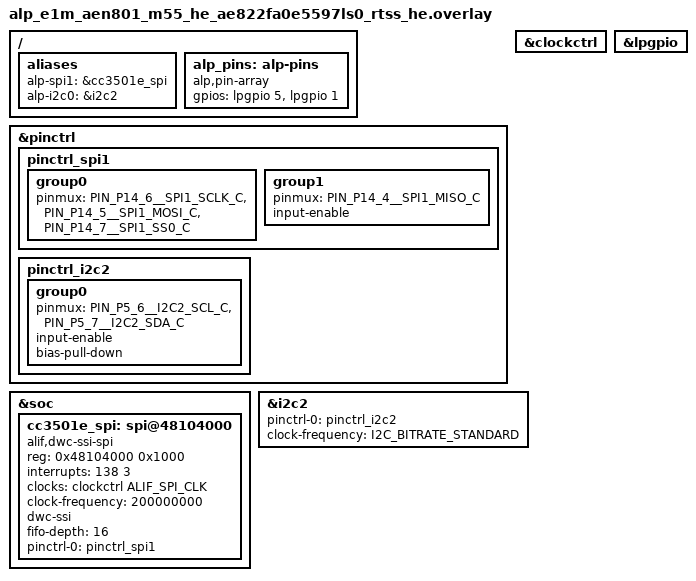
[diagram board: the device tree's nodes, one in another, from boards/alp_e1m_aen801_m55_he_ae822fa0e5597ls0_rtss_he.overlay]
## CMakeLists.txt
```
# SPDX-License-Identifier: Apache-2.0

cmake_minimum_required(VERSION 3.20)

find_package(Zephyr REQUIRED HINTS $ENV{ZEPHYR_BASE})
project(aen_cc3501e_gpio LANGUAGES C)

target_sources(app PRIVATE src/main.c)
# Reusable SoM bring-up helper (cc3501e_bridge_bringup): the one-call CC3501E bridge
# init the example + applications use. Copyable template -- see cc3501e_bridge.h.
target_sources(app PRIVATE src/cc3501e_bridge.c)
# E1M-AEN GPIO-proxy route table: strong override of the WEAK
# cc3501e_gpio_routes[] in src/backends/gpio/cc3501e_proxy_routes_weak.c
# (E1M IO pin_id -> raw CC3501E GPIO). Auto-generated by
# scripts/gen_cc3501e_gpio_routes.py -- do not edit by hand, regenerate.
# Built unconditionally; only consulted when CONFIG_ALP_SDK_GPIO_CC3501E_PROXY
# is enabled (prj.conf).
target_sources(app PRIVATE src/cc3501e_gpio_routes.c)
```

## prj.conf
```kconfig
# SPDX-License-Identifier: Apache-2.0
#
# CONFIG_SPI / CONFIG_GPIO are pulled in from board.yaml's `peripherals:`
# block (via the generated alp.conf); this file carries only the console.
CONFIG_PRINTK=y
CONFIG_LOG=y

# The reset sequence + GPIO-proxy ops use busy/sleep waits; a generous
# main-thread stack keeps the (modest) driver scratch buffers comfortable.
CONFIG_MAIN_STACK_SIZE=4096

# Link the app at the HE MRAM app partition (0x80010000) so its vector table
# matches the ATOC load address (app-zephyr-he.json mramAddress=0x80010000).
# FLASH_BASE is the full MRAM (0x80000000); without this 0x10000 offset the
# image links at 0x80000000 and the SES boots it 64 KB low -> fault/no-boot.
CONFIG_FLASH_LOAD_OFFSET=0x10000

# Route the proxied E1M IOs (cc3501e_gpio_routes[] in src/cc3501e_gpio_routes.c)
# through the CC3501E bridge: alp_gpio_open(ALP_E1M_GPIO_IOxx) for a mapped IO goes over
# the inter-chip link; the Alif's own pins delegate to the platform GPIO driver.
# This demo drives the proxy directly via the cc3501e_gpio_* calls, but building the
# proxy backend keeps the attach call (cc3501e_bridge_bringup) wired the same way an
# application that uses alp_gpio_open(ALP_E1M_GPIO_IO13) would expect.
CONFIG_ALP_SDK_GPIO_CC3501E_PROXY=y
```

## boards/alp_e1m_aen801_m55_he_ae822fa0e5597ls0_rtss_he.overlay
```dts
/*
 * Copyright (c) 2026 Alp Lab AB
 * SPDX-License-Identifier: Apache-2.0
 *
 * Inter-chip wiring for the CC3501E GPIO-proxy demo on the E1M-AEN801 (Alif
 * Ensemble E8, M55-HE).  Identical to the aen-cc3501e-bringup overlay -- the
 * GPIO proxy + camera-enable ops ride the SAME inter-chip SPI1 link + the two
 * host-driven control nets, all from metadata/e1m_modules/aen/inter-chip.tsv:
 *
 *   SPI1.SCK  P14_6   SPI1.MOSI P14_5   SPI1.MISO P14_4   (-> CC3501E GPIO_27/28/29)
 *   WIFI_EN   P15_5 (lpgpio 5)          E_WIFI.NRST P15_1_FLEX (lpgpio 1)
 *
 * "P15" is the Alif low-power GPIO island (lpgpio @ 0x42002000); the
 * _FLEX pads are its pins.  P14 is a main-domain port used here purely as
 * the SPI1 function via pinctrl, so no gpio14 controller node is needed.
 *
 * SPI1 DATA PATH BENCH-VALIDATED 2026-06-20 (E1M-AEN801, M55-HE): the GPIO
 * proxy round-trips over this link (docs/cc3501e-gpio-bench.md, pass=8 fail=0),
 * confirming the P14_4/5/6 pinctrl (SPI1 alt-2, `_C` suffix), the
 * `spi@48104000` base, the LP-GPIO mux (alt-0 default), and the
 * `clock-frequency` workaround.  Still UNCONFIRMED: the SPI1 IRQ number
 * (`interrupts = <138 3>` below). The bridge is hardware-framed by SS0, but
 * this example does not exercise an interrupt-driven SPI path; confirm the IRQ
 * against the AE822 TRM before relying on it.  Addresses/IRQs are still
 * transcribed from the Apache-2.0 alifsemi/zephyr_alif fork + the AE822 TRM
 * (as in zephyr/dts/alif/ensemble_e8_peripherals.dtsi).
 *
 * Also enables i2c2 (P5_6 SCL_C / P5_7 SDA_C) + the `alp-i2c0` alias -- the
 * on-module EEPROM manifest bus alp_hw_info_read() opens as bus_id 0.
 * Without it the manifest read structurally cannot succeed and the banner
 * falls back to the raw board target instead of the SoM identity; see #1870.
 * Same pinctrl (input-enable + bias-pull-down) as
 * examples/peripheral-io/alp-console's bench-validated overlay -- do NOT
 * "correct" the pull direction.
 */

#include <zephyr/dt-bindings/pinctrl/alif-ensemble-pinctrl.h>
#include <zephyr/dt-bindings/gpio/gpio.h>
#include <zephyr/dt-bindings/i2c/i2c.h>

&pinctrl {
	/*
	 * SPI1 master on P14_6 (SCK) / P14_5 (MOSI) / P14_4 (MISO).
	 *
	 * RESOLVED against alif-ensemble-pinctrl.h: the SPI1 functions on these
	 * three pads are alt-2, named with the `_C` suffix
	 * (PIN_P14_6__SPI1_SCLK_C = ALIF_PINMUX(14, 6, 2), etc.).  input-enable
	 * on MISO so the pad can sense the slave's drive (the same read-enable
	 * requirement the I2C pads need on this SoC).
	 */
	pinctrl_spi1: pinctrl_spi1 {
		group0 {
			/* Hardware SS0 chip-select (P14_7 = SPI1_SS0_C) -- dwc-ssi master
			 * drives SS0 per transfer to frame the CC3501E slave.  The slave's
			 * SPIWFF3DMA only shifts bytes while its CS is asserted, so WITHOUT
			 * this pad muxed the bridge is dead (PING never round-trips) -- this
			 * example's overlay had drifted to the pre-r2 CS-less 3-wire wiring
			 * (missing SS0) while its own comment claimed SS0 was muxed; #708. */
			pinmux = <PIN_P14_6__SPI1_SCLK_C>, <PIN_P14_5__SPI1_MOSI_C>,
				 <PIN_P14_7__SPI1_SS0_C>;
		};
		group1 {
			pinmux = <PIN_P14_4__SPI1_MISO_C>;
			input-enable;
		};
	};

	/* I2C2 master (EEPROM manifest bus): SCL P5_6 / SDA P5_7 (_C).  Same
	 * pad config as alp-console's bench-validated overlay -- input-enable
	 * for ACK-detect, bias-pull-down (the pad DSC value Alif's reference
	 * uses; the bus is pulled up on the carrier via R95/R96). */
	pinctrl_i2c2: pinctrl_i2c2 {
		group0 {
			pinmux = <PIN_P5_6__I2C2_SCL_C>, <PIN_P5_7__I2C2_SDA_C>;
			input-enable;
			bias-pull-down;
		};
	};
};

/*
 * DWC_ssi SPI1 (AHB) -- the on-SoM CC3501E inter-chip link.  Deliberately
 * NOT in ensemble_e8_peripherals.dtsi (that dtsi declares only the
 * customer-facing edge SPI0); this is the SoM-internal Wi-Fi link, so it
 * lives in the consuming app's overlay.  Same driver + flags as spi0
 * (compatible "alif,dwc-ssi-spi", dwc-ssi layout, fifo-depth 16,
 * frequency-only ALIF_SPI_CLK).
 *
 * reg 0x48104000 = SPI1 base (spi0 is 0x48103000, +0x1000/instance).
 * BENCH-TBD: interrupts = <138 3> follows the consecutive pattern from
 * spi0's IRQ 137 -- confirm SPI1_IRQ against the fork's e1.dtsi / TRM.
 *
 * No cs-gpios: P14_7 is muxed as SPI1_SS0_C above and the dwc-ssi peripheral
 * drives hardware SS0 per transfer.  The host opens ALP_SPI_NO_CS so no GPIO CS
 * is installed, allowing the SPI driver to use its hardware slave-select path.
 */
&clockctrl {
	status = "okay";
};

&soc {
	cc3501e_spi: spi@48104000 {
		compatible = "alif,dwc-ssi-spi";
		#address-cells = <1>;
		#size-cells = <0>;
		reg = <0x48104000 0x1000>;
		interrupts = <138 3>;          /* BENCH-TBD: confirm SPI1 IRQ */
		clocks = <&clockctrl ALIF_SPI_CLK>;
		/*
		 * ROOT-CAUSE FIX 2026-06-16: spi_dw_alif's configure takes the
		 * clock-control path when no clock-frequency is set, and that path
		 * fails (-EINVAL) for the gateless dummy ALIF_SPI_CLK -> every
		 * transceive returned ALP_ERR_INVAL with zero SCLK (witness fail_step=1,
		 * zerr=-EINVAL). Providing the SSI input clock here makes the driver
		 * use it directly and skip the failing clock-control path. The SSI
		 * functional clock is 200 MHz (E8 HWRM); BAUDR = clk/freq_hz.
		 */
		clock-frequency = <200000000>; /* real SSI functional clock (was mis-set 400M -- halves the requested SCLK; proven via BAUDR scaling, parity with the bringup/tour overlays) */
		dwc-ssi;
		fifo-depth = <16>;
		pinctrl-0 = <&pinctrl_spi1>;
		pinctrl-names = "default";
		status = "okay";
	};
};

/*
 * Enable the LP GPIO island so WIFI_EN (P15_5) and E_WIFI.NRST
 * (P15_1_FLEX) are drivable as outputs.  gpio_dw needs no clocks/pinctrl
 * on the controller, and the pad->GPIO mux needs no pinctrl group either:
 * RESOLVED against alif-ensemble-pinctrl.h -- P15_1/P15_5 function 0 (the
 * reset default) IS LPGPIO (PIN_P15_x__LPGPIO = ALIF_PINMUX(15, x, 0)).
 */
&lpgpio {
	status = "okay";
};

&i2c2 {
	status = "okay";
	pinctrl-0 = <&pinctrl_i2c2>;
	pinctrl-names = "default";
	clock-frequency = <I2C_BITRATE_STANDARD>;   /* 100 kHz */
};

/ {
	aliases {
		/* bus_id 1 in alp_spi_open() -> this controller. */
		alp-spi1 = &cc3501e_spi;
		alp-i2c0 = &i2c2;   /* bus 0 for alp_hw_info_read() -> EEPROM manifest */
	};

	/*
	 * Compact 2-entry control array for the SoM-internal CC3501E nets, in
	 * the order the app's CC3501E_BRIDGE_PIN_* indices expect.  These are NOT
	 * E1M edge pads, so this app intentionally does NOT use the 52-slot
	 * positional E1M map; a production board file appends such SoM-internal
	 * control nets after the E1M pad slots.
	 */
	alp_pins: alp-pins {
		compatible = "alp,pin-array";
		gpios = <&lpgpio 5 GPIO_ACTIVE_HIGH>,   /* [0] WIFI_EN     (P15_5)      */
			<&lpgpio 1 GPIO_ACTIVE_HIGH>;   /* [1] E_WIFI.NRST (P15_1_FLEX) */
	};
};
```

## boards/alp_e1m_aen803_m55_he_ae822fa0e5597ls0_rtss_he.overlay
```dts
/*
 * Copyright (c) 2026 Alp Lab AB
 * SPDX-License-Identifier: Apache-2.0
 *
 * Inter-chip wiring for the CC3501E GPIO-proxy demo on the E1M-AEN803 (Alif
 * Ensemble E8, M55-HE).  Identical to the aen-cc3501e-bringup overlay -- the
 * GPIO proxy + camera-enable ops ride the SAME inter-chip SPI1 link + the two
 * host-driven control nets, all from metadata/e1m_modules/aen/inter-chip.tsv:
 *
 *   SPI1.SCK  P14_6   SPI1.MOSI P14_5   SPI1.MISO P14_4   (-> CC3501E GPIO_27/28/29)
 *   WIFI_EN   P15_5 (lpgpio 5)          E_WIFI.NRST P15_1_FLEX (lpgpio 1)
 *
 * "P15" is the Alif low-power GPIO island (lpgpio @ 0x42002000); the
 * _FLEX pads are its pins.  P14 is a main-domain port used here purely as
 * the SPI1 function via pinctrl, so no gpio14 controller node is needed.
 *
 * SPI1 DATA PATH BENCH-VALIDATED 2026-06-20 (E1M-AEN801, M55-HE): the GPIO
 * proxy round-trips over this link (docs/cc3501e-gpio-bench.md, pass=8 fail=0),
 * confirming the P14_4/5/6 pinctrl (SPI1 alt-2, `_C` suffix), the
 * `spi@48104000` base, the LP-GPIO mux (alt-0 default), and the
 * `clock-frequency` workaround.  Still UNCONFIRMED: the SPI1 IRQ number
 * (`interrupts = <138 3>` below). The bridge is hardware-framed by SS0, but
 * this example does not exercise an interrupt-driven SPI path; confirm the IRQ
 * against the AE822 TRM before relying on it.  Addresses/IRQs are still
 * transcribed from the Apache-2.0 alifsemi/zephyr_alif fork + the AE822 TRM
 * (as in zephyr/dts/alif/ensemble_e8_peripherals.dtsi).  This SPI1/GPIO pad
 * path is identical on the AEN803's same AE822 M55-HE die, but this
 * backfilled overlay has not itself been separately bench-run on AEN803
 * (Refs #2128) -- unbuilt as of this PR.
 *
 * Also enables i2c2 (P5_6 SCL_C / P5_7 SDA_C) + the `alp-i2c0` alias -- the
 * on-module EEPROM manifest bus alp_hw_info_read() opens as bus_id 0.
 * Without it the manifest read structurally cannot succeed and the banner
 * falls back to the raw board target instead of the SoM identity; see #1870.
 * Same pinctrl (input-enable + bias-pull-down) as
 * examples/peripheral-io/alp-console's bench-validated overlay -- do NOT
 * "correct" the pull direction.
 */

#include <zephyr/dt-bindings/pinctrl/alif-ensemble-pinctrl.h>
#include <zephyr/dt-bindings/gpio/gpio.h>
#include <zephyr/dt-bindings/i2c/i2c.h>

&pinctrl {
	/*
	 * SPI1 master on P14_6 (SCK) / P14_5 (MOSI) / P14_4 (MISO).
	 *
	 * RESOLVED against alif-ensemble-pinctrl.h: the SPI1 functions on these
	 * three pads are alt-2, named with the `_C` suffix
	 * (PIN_P14_6__SPI1_SCLK_C = ALIF_PINMUX(14, 6, 2), etc.).  input-enable
	 * on MISO so the pad can sense the slave's drive (the same read-enable
	 * requirement the I2C pads need on this SoC).
	 */
	pinctrl_spi1: pinctrl_spi1 {
		group0 {
			/* Hardware SS0 chip-select (P14_7 = SPI1_SS0_C) -- dwc-ssi master
			 * drives SS0 per transfer to frame the CC3501E slave.  The slave's
			 * SPIWFF3DMA only shifts bytes while its CS is asserted, so WITHOUT
			 * this pad muxed the bridge is dead (PING never round-trips) -- this
			 * example's overlay had drifted to the pre-r2 CS-less 3-wire wiring
			 * (missing SS0) while its own comment claimed SS0 was muxed; #708. */
			pinmux = <PIN_P14_6__SPI1_SCLK_C>, <PIN_P14_5__SPI1_MOSI_C>,
				 <PIN_P14_7__SPI1_SS0_C>;
		};
		group1 {
			pinmux = <PIN_P14_4__SPI1_MISO_C>;
			input-enable;
		};
	};

	/* I2C2 master (EEPROM manifest bus): SCL P5_6 / SDA P5_7 (_C).  Same
	 * pad config as alp-console's bench-validated overlay -- input-enable
	 * for ACK-detect, bias-pull-down (the pad DSC value Alif's reference
	 * uses; the bus is pulled up on the carrier via R95/R96). */
	pinctrl_i2c2: pinctrl_i2c2 {
		group0 {
			pinmux = <PIN_P5_6__I2C2_SCL_C>, <PIN_P5_7__I2C2_SDA_C>;
			input-enable;
			bias-pull-down;
		};
	};
};

/*
 * DWC_ssi SPI1 (AHB) -- the on-SoM CC3501E inter-chip link.  Deliberately
 * NOT in ensemble_e8_peripherals.dtsi (that dtsi declares only the
 * customer-facing edge SPI0); this is the SoM-internal Wi-Fi link, so it
 * lives in the consuming app's overlay.  Same driver + flags as spi0
 * (compatible "alif,dwc-ssi-spi", dwc-ssi layout, fifo-depth 16,
 * frequency-only ALIF_SPI_CLK).
 *
 * reg 0x48104000 = SPI1 base (spi0 is 0x48103000, +0x1000/instance).
 * BENCH-TBD: interrupts = <138 3> follows the consecutive pattern from
 * spi0's IRQ 137 -- confirm SPI1_IRQ against the fork's e1.dtsi / TRM.
 *
 * No cs-gpios: P14_7 is muxed as SPI1_SS0_C above and the dwc-ssi peripheral
 * drives hardware SS0 per transfer.  The host opens ALP_SPI_NO_CS so no GPIO CS
 * is installed, allowing the SPI driver to use its hardware slave-select path.
 */
&clockctrl {
	status = "okay";
};

&soc {
	cc3501e_spi: spi@48104000 {
		compatible = "alif,dwc-ssi-spi";
		#address-cells = <1>;
		#size-cells = <0>;
		reg = <0x48104000 0x1000>;
		interrupts = <138 3>;          /* BENCH-TBD: confirm SPI1 IRQ */
		clocks = <&clockctrl ALIF_SPI_CLK>;
		/*
		 * ROOT-CAUSE FIX 2026-06-16: spi_dw_alif's configure takes the
		 * clock-control path when no clock-frequency is set, and that path
		 * fails (-EINVAL) for the gateless dummy ALIF_SPI_CLK -> every
		 * transceive returned ALP_ERR_INVAL with zero SCLK (witness fail_step=1,
		 * zerr=-EINVAL). Providing the SSI input clock here makes the driver
		 * use it directly and skip the failing clock-control path. The SSI
		 * functional clock is 200 MHz (E8 HWRM); BAUDR = clk/freq_hz.
		 */
		clock-frequency = <200000000>; /* real SSI functional clock (was mis-set 400M -- halves the requested SCLK; proven via BAUDR scaling, parity with the bringup/tour overlays) */
		dwc-ssi;
		fifo-depth = <16>;
		pinctrl-0 = <&pinctrl_spi1>;
		pinctrl-names = "default";
		status = "okay";
	};
};

/*
 * Enable the LP GPIO island so WIFI_EN (P15_5) and E_WIFI.NRST
 * (P15_1_FLEX) are drivable as outputs.  gpio_dw needs no clocks/pinctrl
 * on the controller, and the pad->GPIO mux needs no pinctrl group either:
 * RESOLVED against alif-ensemble-pinctrl.h -- P15_1/P15_5 function 0 (the
 * reset default) IS LPGPIO (PIN_P15_x__LPGPIO = ALIF_PINMUX(15, x, 0)).
 */
&lpgpio {
	status = "okay";
};

&i2c2 {
	status = "okay";
	pinctrl-0 = <&pinctrl_i2c2>;
	pinctrl-names = "default";
	clock-frequency = <I2C_BITRATE_STANDARD>;   /* 100 kHz */
};

/ {
	aliases {
		/* bus_id 1 in alp_spi_open() -> this controller. */
		alp-spi1 = &cc3501e_spi;
		alp-i2c0 = &i2c2;   /* bus 0 for alp_hw_info_read() -> EEPROM manifest */
	};

	/*
	 * Compact 2-entry control array for the SoM-internal CC3501E nets, in
	 * the order the app's CC3501E_BRIDGE_PIN_* indices expect.  These are NOT
	 * E1M edge pads, so this app intentionally does NOT use the 52-slot
	 * positional E1M map; a production board file appends such SoM-internal
	 * control nets after the E1M pad slots.
	 */
	alp_pins: alp-pins {
		compatible = "alp,pin-array";
		gpios = <&lpgpio 5 GPIO_ACTIVE_HIGH>,   /* [0] WIFI_EN     (P15_5)      */
			<&lpgpio 1 GPIO_ACTIVE_HIGH>;   /* [1] E_WIFI.NRST (P15_1_FLEX) */
	};
};
```

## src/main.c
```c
/*
 * Copyright 2026 Alp Lab AB
 * SPDX-License-Identifier: Apache-2.0
 *
 * aen-cc3501e-gpio -- drive + read a PROXIED GPIO and the camera-enable
 * LDOs on the on-module TI CC3501E Wi-Fi 6 + BLE 5.4 coprocessor, from the
 * Alif Ensemble E8 host (M55-HE), over the inter-chip SPI bridge.
 *
 * This is the *Alif (host) side*; its peer is the ALP-authored firmware
 * that runs on the CC3501E's own Cortex-M33 (cc3501e-bridge-firmware:, embedded
 * per ADR 0015 -- like the gd32-bridge).  It is the sibling of
 * examples/aen/aen-cc3501e-bringup: it brings the bridge up the SAME way
 * (one call to cc3501e_bridge_bringup()), then exercises a different slice
 * of the firmware -- the GPIO proxy + camera enables -- instead of the
 * Wi-Fi/BLE control path.
 *
 *
 * ==== WHAT IS THE "GPIO PROXY"? ====================================
 *
 * Several E1M edge IO pads on the AEN SoM are NOT wired to an Alif pin --
 * they are wired to a *CC3501E* GPIO.  The CC3501E sits between the Alif
 * and those pads.  So when the application asks for "IO13", the SDK cannot
 * toggle an Alif register; it must ask the CC3501E firmware to toggle the
 * pad on its behalf, over the SPI bridge.  That indirection -- host op ->
 * bridge frame -> CC3501E drives the pad -- is the GPIO *proxy*.
 *
 * Two ways to use it:
 *
 *   1. PORTABLE (what an application normally writes):
 *        alp_gpio_t *io = alp_gpio_open(ALP_E1M_GPIO_IO13);
 *        alp_gpio_configure(io, ALP_GPIO_OUTPUT, ALP_GPIO_PULL_NONE);
 *        alp_gpio_write(io, true);
 *      With CONFIG_ALP_SDK_GPIO_CC3501E_PROXY=y and the route table in
 *      src/cc3501e_gpio_routes.c, the SDK silently routes ALP_E1M_GPIO_IO13
 *      over the bridge to raw CC3501E GPIO_13 -- the app never names the
 *      coprocessor.  (This build enables that backend so the bring-up
 *      helper's alp_gpio_cc3501e_attach() runs, exactly as a portable app
 *      would expect.)
 *
 *   2. DIRECT (what THIS demo does, to make the bridge op visible):
 *        cc3501e_gpio_configure(&fw, 13 [raw pad], DIR_OUTPUT, PULL_NONE, t);
 *        cc3501e_gpio_write(&fw, 13, true, t);
 *      Here `pad` is the RAW CC3501E GPIO index.  We call the chip driver
 *      directly so each bridge transaction is explicit in the teaching
 *      log -- it is the same wire op the portable path emits underneath.
 *
 * The route table (src/cc3501e_gpio_routes.c) ties ALP_E1M_GPIO_IO13 -> raw
 * CC3501E GPIO 13, so "pad 13" below is the same pad a portable
 * alp_gpio_open(ALP_E1M_GPIO_IO13) would reach.
 *
 *
 * ==== THE r2 HOST-IRQ CAVEAT (READ BEFORE USING INTERRUPTS) ========
 *
 * This HW rev uses hardware SS0 for SPI framing and an OPTIONAL READY input
 * for per-phase gating (unwired, fw->ready_pin stays NULL, in this app --
 * see src/cc3501e_bridge.c), but it still does not expose GPIO edge events
 * as portable application callbacks.  The Alif is always the SPI master;
 * the CC3501E is always the slave.  Without a dedicated async event
 * delivery path, the slave cannot
 * spontaneously tell the master "an edge happened on a GPIO".  So:
 *
 *   - cc3501e_gpio_set_interrupt() ARMS the edge on the CC3501E's own GPIO
 *     controller -- that part is real, it latches edges in the coprocessor.
 *   - but the async ALP_CC3501E_EVT_GPIO_INTERRUPT frame is not a portable
 *     callback path in this example.  The host must poll cc3501e_gpio_read() to
 *     observe a level change; the armed interrupt does not call you back.
 *
 * The step below therefore only proves the ARM round-trips; do not build a
 * design that depends on EVT_GPIO_INTERRUPT delivery on this rev.
 *
 *
 * ==== BENCH CONTRACT ===============================================
 *
 * Each step prints ONE stable line a sibling bench script greps:
 *     GPIO_TEST: <step> <PASS|FAIL>
 * with these exact <step> tokens, in order:
 *     gpio_config_out gpio_write_high gpio_write_low gpio_config_in
 *     gpio_read cam_enable cam_disable gpio_irq_arm
 * and a final:
 *     GPIO_TEST: SUMMARY pass=<n> fail=<n>
 * Keep these strings byte-for-byte -- the grep depends on them.
 *
 * NOTE ON native_sim: the CI build target (native_sim/native/64) has only
 * an EMULATED SPI controller with no CC3501E attached, so every bridge op
 * times out and the contract lines print FAIL there.  That is EXPECTED:
 * native_sim proves the example *builds* (twister build_only); the
 * PASS/FAIL contract is a SILICON bench signal, read on real hardware.
 *
 * This file is ~50 % comment by design: examples are documentation for
 * hand-written firmware, not just runnable code.
 */

#include <stdio.h>

#include <zephyr/kernel.h>

#include "alp/peripheral.h"
#include "alp/chips/cc3501e.h"

#include "cc3501e_bridge.h" /* cc3501e_bridge_bringup() -- the SoM bring-up helper */

/*
 * The proxied pad this demo drives.  RAW CC3501E GPIO index 13, which the
 * route table (src/cc3501e_gpio_routes.c) maps to the portable E1M IO
 * ALP_E1M_GPIO_IO13 (= I2S_SELECT on the E1M-AEN netlist).  Driving it has no
 * destructive side-effect on the bench, which is why it is the demo pad.
 */
#define DEMO_PAD 13u

/*
 * Camera-enable LDO index.  0 = CAM_EN_LDO0 (CC35 GPIO_1); 1 = CAM_EN_LDO1
 * (CC35 GPIO_0) per the BDE-BW35N U4 netlist.  We exercise LDO0.
 */
#define DEMO_CAM 0u

/*
 * Per-request budget for the synchronous GPIO/camera bridge ops.  These
 * are fast in the firmware (no worker, unlike the Wi-Fi helpers), so a
 * short timeout is plenty; it also bounds how long native_sim sits on each
 * (failing) op before recording FAIL and moving on.
 */
#define DEMO_OP_TIMEOUT_MS 100u

/*
 * ==== WHY THIS EXAMPLE NEEDS A LIVENESS GATE (read before touching #708) ==
 *
 * cc3501e_bridge_bringup() -> cc3501e_reset() only does a BLIND boot-settle
 * delay (see chips/cc3501e/cc3501e_core.c) -- it never exchanges a byte with
 * the module, so it returns as soon as its own timer expires, NOT when the
 * firmware is actually answering.  The --wifi --ble image is slow to arm its
 * SPI slave: lwIP's tcpip_init() and the crypto/Board_init sequence run
 * BEFORE transport_spi_init(), and the Puya cold-boot flash bug (see
 * cc3501e_hard_reset()'s comment) sometimes needs a SECOND hard reset before
 * the module answers at all.  Meanwhile each of the 8 gpio/cam ops below has
 * only a DEMO_OP_TIMEOUT_MS (100 ms) budget -- ~0.9 s total for all 8 -- so
 * without a gate they race the boot and ALL eight TIMEOUT before the slave
 * is armed, even though the link comes up fine a second or two later.  (The
 * bringup soak already has this "hard-reset again if one re-boot is not
 * enough" retry -- cc3501e_core.c:119-121 -- this gate is the same idea
 * applied here, mirroring aen-cc3501e-companion-tour's tour_ping().)
 *
 * The fix is NOT a bigger DEMO_OP_TIMEOUT_MS (that just slows down every
 * op, including the ones that are genuinely broken) -- it is to not START
 * the ops until a cheap, zero-payload PING actually round-trips.
 */
#define GPIO_PING_RETRIES 25u  /* poll-by-repeat budget per attempt, mirrors tour_ping() */
#define GPIO_PING_GAP_MS  200u /* gap between PING attempts (5 s worst case per attempt) */
#define GPIO_LINK_REBOOTS 3u   /* extra cc3501e_hard_reset() attempts if PING never lands */

/*
 * Emit one bench-contract line and fold the result into the running
 * tally.  `ok` is the boolean a step computed from its alp_status_t; we
 * print the exact "GPIO_TEST: <step> PASS|FAIL" the bench script greps and
 * bump pass/fail so main() can print the SUMMARY at the end.
 */
static void report(const char *step, bool ok, unsigned *pass, unsigned *fail)
{
	printf("GPIO_TEST: %s %s\n", step, ok ? "PASS" : "FAIL");
	if (ok) {
		(*pass)++;
	} else {
		(*fail)++;
	}
}

/*
 * Liveness gate -- see the "WHY" block above DEMO_OP_TIMEOUT_MS.  Spins a
 * zero-payload PING up to GPIO_PING_RETRIES times (GPIO_PING_GAP_MS apart);
 * PING is cheap (no worker, no radio) so this is a fast poll, not a slow
 * one.  If a whole PING attempt never lands, cc3501e_hard_reset() gives the
 * module a second boot (the Puya cold-boot workaround -- the first boot can
 * simply fail to launch the vendor image) and the PING loop runs again, up
 * to GPIO_LINK_REBOOTS times.  Returns true once a PING succeeds.
 */
static bool gpio_wait_for_link(cc3501e_t *fw)
{
	for (unsigned reboot = 0u; reboot <= GPIO_LINK_REBOOTS; ++reboot) {
		for (unsigned i = 0u; i < GPIO_PING_RETRIES; ++i) {
			if (cc3501e_ping(fw) == ALP_OK) {
				printf("[cc3501e-gpio] link up (PING ok after %u) -- running gpio ops\n", i + 1u);
				return true;
			}
			alp_delay_ms(GPIO_PING_GAP_MS);
		}
		/* A full PING budget elapsed with no reply -- the module may have
		 * hit the Puya cold-boot bug (first boot never launches the vendor
		 * image).  Give it one more re-boot with the rails kept up and try
		 * again, unless we are already on the last allowed attempt. */
		if (reboot < GPIO_LINK_REBOOTS) {
			printf("[cc3501e-gpio] PING never answered after %u attempts -- issuing "
			       "hard reset %u/%u and retrying\n",
			       GPIO_PING_RETRIES,
			       reboot + 1u,
			       GPIO_LINK_REBOOTS);
			(void)cc3501e_hard_reset(fw);
		}
	}
	printf("[cc3501e-gpio] CC3501E never answered PING after %u hard reset(s) -- the gpio "
	       "ops below will still run (and report FAIL) so the bench SUMMARY stays complete; "
	       "check WIFI_EN power, the SPI1 pinmux, and that the --wifi --ble firmware is "
	       "actually flashed\n",
	       GPIO_LINK_REBOOTS);
	return false;
}

int main(void)
{
	printf("\n[cc3501e-gpio] E1M-AEN CC3501E GPIO-proxy + camera-enable demo\n");

	unsigned pass = 0u;
	unsigned fail = 0u;

	/*
	 * Bring up the SoM's CC3501E coprocessor in ONE call -- exactly like
	 * aen-cc3501e-bringup.  cc3501e_bridge_bringup() opens the inter-chip
	 * SPI bridge + the WIFI_EN/nRESET control pins, binds them, attaches
	 * the GPIO proxy backend (so a portable alp_gpio_open(ALP_E1M_GPIO_IO13)
	 * would route over the bridge), and runs the power + reset sequence
	 * (TI SWRU626 + the Puya cold-boot hard-reset).  Leaves WIFI_EN HIGH.
	 *
	 * STATIC, not a stack local (#1868): sizeof(cc3501e_t) is ~32 KB
	 * (measured -- rx_scratch/tx_scratch/wifi_scan_buf/ble_scan_buf/
	 * evt_buf/sock_buf/spi1_{tx,rx}_buf are each sized off the v5
	 * ALP_CC3501E_MAX_PAYLOAD=4096) against CONFIG_MAIN_STACK_SIZE=4096,
	 * so as a local the prologue's frame reservation alone crosses
	 * PSPLIM and the M55 raises a UsageFault at main() entry -- before
	 * even this function's first printf runs.  Same fix, same reason,
	 * as aen-cc3501e-bringup's `fw`.
	 */
	static cc3501e_t fw;
	alp_status_t     s = cc3501e_bridge_bringup(&fw);
	if (s == ALP_ERR_NOT_PRESENT_ON_THIS_SOC) {
		/* The backend authority itself says the SPI bus / control pins are
		 * absent (wrong board overlay) -- a bench/board limitation, not a
		 * bug in this app (same rule as an ALP_ERR_NOSUPPORT boot-authority
		 * answer elsewhere in this diff: aen-alp-rpc/src/main.c,
		 * aen-dualcore-doorbell/src/main.c). Nothing to drive -- bail. */
		printf("[cc3501e-gpio] bridge bring-up skipped (SPI bus %u / WIFI_EN+nRESET "
		       "absent? err=%d) -- check the board overlay\n",
		       CC3501E_BRIDGE_SPI_BUS_ID,
		       (int)alp_last_error());
		printf("RESULT SKIP: cc3501e_bridge_bringup -> NOT_PRESENT_ON_THIS_SOC (SPI bus %u / "
		       "WIFI_EN+nRESET absent? err=%d)\n",
		       CC3501E_BRIDGE_SPI_BUS_ID,
		       (int)alp_last_error());
		return 0;
	}
	printf("[cc3501e-gpio] cc3501e bridge bring-up -> %d%s\n",
	       (int)s,
	       (s == ALP_ERR_NOSUPPORT) ? " (control pins not bound?)" : "");

	/*
	 * Liveness gate -- see #708.  cc3501e_bridge_bringup() only waits out a
	 * BLIND boot-settle timer (no wire exchange), so it can return before
	 * the --wifi --ble firmware has actually armed its SPI slave.  Do not
	 * skip straight to the 8 gpio/cam ops (each has only a 100 ms budget):
	 * confirm the link is live with a cheap PING first, retrying through
	 * extra hard resets if needed.  We deliberately do NOT early-return on
	 * total failure -- the bench script's grep contract requires all 8 step
	 * lines plus the SUMMARY, so the ops still run below (and will FAIL,
	 * correctly reporting a dead link instead of going silent).
	 */
	(void)gpio_wait_for_link(&fw);

	/*
	 * Step 1 -- configure the proxied pad as a push-pull OUTPUT with no
	 * internal pull.  This is GPIO_CONFIGURE (0x50) over the bridge: the
	 * host hands the CC3501E the pad index + direction + pull and the
		 * firmware programs its own GPIO controller.  ALP_OK = the firmware
		 * accepted the config and answered over the hardware-framed bridge.
	 */
	s = cc3501e_gpio_configure(
	    &fw, DEMO_PAD, ALP_CC3501E_GPIO_DIR_OUTPUT, ALP_CC3501E_GPIO_PULL_NONE, DEMO_OP_TIMEOUT_MS);
	report("gpio_config_out", s == ALP_OK, &pass, &fail);

	/*
	 * Step 2 -- drive the pad HIGH.  GPIO_WRITE (0x51) with level=true.
	 * On silicon a meter on the E1M IO13 pad reads ~3V3 after this.
	 */
	s = cc3501e_gpio_write(&fw, DEMO_PAD, true, DEMO_OP_TIMEOUT_MS);
	report("gpio_write_high", s == ALP_OK, &pass, &fail);

	/*
	 * Step 3 -- drive the pad LOW.  Same op, level=false; the pad returns
	 * to ~0 V.  Writing both levels proves the firmware honours the value
	 * field, not just that the op round-trips.
	 */
	s = cc3501e_gpio_write(&fw, DEMO_PAD, false, DEMO_OP_TIMEOUT_MS);
	report("gpio_write_low", s == ALP_OK, &pass, &fail);

	/*
	 * Step 4 -- reconfigure the SAME pad as an INPUT with the internal
	 * pull-UP enabled.  GPIO_CONFIGURE again, direction=INPUT, pull=UP.
	 * The on-die pull is documented as weak; a board needing a firm level
	 * adds an external resistor.  With nothing else driving the net the
	 * pull-up should make the next read sense HIGH.
	 */
	s = cc3501e_gpio_configure(
	    &fw, DEMO_PAD, ALP_CC3501E_GPIO_DIR_INPUT, ALP_CC3501E_GPIO_PULL_UP, DEMO_OP_TIMEOUT_MS);
	report("gpio_config_in", s == ALP_OK, &pass, &fail);

	/*
	 * Step 5 -- READ the pad back.  GPIO_READ (0x52): the firmware samples
	 * its pad and returns the level in the reply payload.  We print the
	 * sensed level for the bench log; PASS just means the read op itself
	 * succeeded (the actual level depends on what is wired to the pad).
	 */
	bool level = false;
	s          = cc3501e_gpio_read(&fw, DEMO_PAD, &level, DEMO_OP_TIMEOUT_MS);
	if (s == ALP_OK) {
		printf("[cc3501e-gpio] pad %u reads %s\n", DEMO_PAD, level ? "HIGH" : "LOW");
	}
	report("gpio_read", s == ALP_OK, &pass, &fail);

	/*
	 * Step 6 -- ENABLE camera LDO0.  cc3501e_cam_enable(which=0, on=true)
	 * sends CAM_ENABLE (0x60); the firmware asserts the LDO's enable pin
	 * (CC35 GPIO_1).  On a camera-fitted board this powers the sensor rail.
	 */
	s = cc3501e_cam_enable(&fw, DEMO_CAM, true, DEMO_OP_TIMEOUT_MS);
	report("cam_enable", s == ALP_OK, &pass, &fail);

	/*
	 * Step 7 -- DISABLE camera LDO0.  cc3501e_cam_enable(which=0, on=false)
	 * sends CAM_DISABLE (0x61); the firmware deasserts the enable.  We
	 * power it back down so the demo leaves the rail in its idle state.
	 */
	s = cc3501e_cam_enable(&fw, DEMO_CAM, false, DEMO_OP_TIMEOUT_MS);
	report("cam_disable", s == ALP_OK, &pass, &fail);

	/*
	 * Step 8 -- ARM a RISING-edge interrupt on the proxied pad.
	 * GPIO_SET_INTERRUPT (0x53), edge=RISING, enabled=true.
	 *
	 * IMPORTANT (see the caveat at the top): this ONLY arms the edge on
	 * the CC3501E's GPIO controller.  The async EVT_GPIO_INTERRUPT frame is
	 * not a portable callback path in this example.  A PASS here means "the
	 * firmware accepted the arm request", NOT "you will get an interrupt
	 * callback".  To observe the edge today you must POLL cc3501e_gpio_read()
	 * in a loop.  (EDGE_BOTH is unsupported on the CC35xx controller -- arm
	 * RISING or FALLING, never both.)
	 */
	s = cc3501e_gpio_set_interrupt(
	    &fw, DEMO_PAD, ALP_CC3501E_GPIO_EDGE_RISING, true, DEMO_OP_TIMEOUT_MS);
	report("gpio_irq_arm", s == ALP_OK, &pass, &fail);

	/*
	 * Final contract line: the running tally.  A bench run on silicon with
	 * the CC3501E firmware up expects pass=8 fail=0; under native_sim
	 * (emul SPI, no slave) expect pass=0 fail=8 -- the build, not the
	 * round-trip, is what the CI target proves.
	 */
	printf("GPIO_TEST: SUMMARY pass=%d fail=%d\n", (int)pass, (int)fail);

	/* RESULT verdict, gated on the SUMMARY tally above -- report() is the
	 * ONLY thing that increments pass/fail, and every one of the 8 steps
	 * calls it, so fail==0 here means all 8 bridge ops genuinely returned
	 * ALP_OK (not that main() merely reached this line: a dead link fails
	 * every step via gpio_wait_for_link()'s own comment above, and native_sim
	 * -- no CC3501E attached -- always lands here with fail=8). */
	if (fail == 0u) {
		printf("RESULT PASS: all %u cc3501e gpio/cam bridge ops ok\n", pass);
	} else {
		printf("RESULT FAIL: %u/%u cc3501e gpio/cam bridge op(s) failed -- see GPIO_TEST "
		       "lines above\n",
		       fail,
		       pass + fail);
	}

	/* The bridge SPI + control pins are owned by cc3501e_bridge_bringup();
	 * a real app that tears down would add a cc3501e_bridge_teardown(). */
	return 0;
}
```

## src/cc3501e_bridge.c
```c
/*
 * SPDX-License-Identifier: Apache-2.0
 * Copyright 2026 Alp Lab AB
 *
 * E1M-AEN SoM CC3501E bridge bring-up helper -- see cc3501e_bridge.h.
 */

#include "cc3501e_bridge.h"

#if defined(CONFIG_BOARD_ALP_E1M_AEN801_M55_HE)
#include <zephyr/arch/cpu.h>
#include <zephyr/sys/sys_io.h>
/*
 * AEN LP-pad mux (Alif Ensemble E8, M55-HE).  WIFI_EN (P15_5) and nRESET (P15_1)
 * are on the Alif LP-GPIO island, bound by the generic snps,designware-gpio driver
 * which does NOT apply Alif pinctrl -- so the LP pads stay un-muxed and their output
 * drivers OFF (confirmed on silicon: WIFI_EN never powers the CC3501E until these
 * regs are set).  0x23 = the Alif GPIO-output pad config (driver + read-enable +
 * drive strength).  TODO: drop this raw poke once the Alif GPIO backend muxes the LP
 * island via pinctrl.
 */
#define ALIF_LPGPIO_PADCTRL_BASE 0x42007000u
#define ALIF_PAD_GPIO_OUTPUT     0x23u
static void aen_lp_pads_enable_output(void)
{
	sys_write32(ALIF_PAD_GPIO_OUTPUT, ALIF_LPGPIO_PADCTRL_BASE + 5u * 4u); /* P15_5 WIFI_EN */
	sys_write32(ALIF_PAD_GPIO_OUTPUT, ALIF_LPGPIO_PADCTRL_BASE + 1u * 4u); /* P15_1 nRESET  */
}
#else
static inline void aen_lp_pads_enable_output(void)
{
}
#endif

alp_status_t cc3501e_bridge_bringup(cc3501e_t *fw)
{
	if (fw == NULL) {
		return ALP_ERR_INVAL;
	}

	/* 1. Control pins: WIFI_EN (supply gate) + nRESET.  These are Alif LP-GPIO
	 *    pads, not E1M edge pads -- the SoM owns them. */
	alp_gpio_t *wifi_en = alp_gpio_open(CC3501E_BRIDGE_PIN_WIFI_EN);
	alp_gpio_t *nrst    = alp_gpio_open(CC3501E_BRIDGE_PIN_NRST);
	if (wifi_en == NULL || nrst == NULL) {
		if (wifi_en != NULL) {
			alp_gpio_close(wifi_en);
		}
		if (nrst != NULL) {
			alp_gpio_close(nrst);
		}
		return ALP_ERR_NOT_PRESENT_ON_THIS_SOC;
	}
	aen_lp_pads_enable_output();
	(void)alp_gpio_configure(wifi_en, ALP_GPIO_OUTPUT, ALP_GPIO_PULL_NONE);
	(void)alp_gpio_configure(nrst, ALP_GPIO_OUTPUT, ALP_GPIO_PULL_NONE);

	/* 2. Inter-chip SPI (Alif = master).  CS is the dwc-ssi hardware SS0
	 *    muxed on P14_7; the app passes ALP_SPI_NO_CS so no software GPIO CS
	 *    is installed and the SPI controller drives SS0 per transfer.  Mode 0
	 *    matches the CC3501E vendor image frameFormat. */
	alp_spi_t *spi = alp_spi_open(&(alp_spi_config_t){
	    .bus_id        = CC3501E_BRIDGE_SPI_BUS_ID,
	    .freq_hz       = CC3501E_BRIDGE_SPI_FREQ_HZ,
	    .mode          = ALP_SPI_MODE_0,
	    .bits_per_word = 8u,
	    .cs_pin_id     = ALP_SPI_NO_CS,
	});
	if (spi == NULL) {
		alp_gpio_close(wifi_en);
		alp_gpio_close(nrst);
		return ALP_ERR_NOT_PRESENT_ON_THIS_SOC;
	}

#if CC3501E_BRIDGE_RX_SAMPLE_DLY > 0
	/* Raise the SCLK past 1 MHz: the DW SSI RX_SAMPLE_DLY register (0xf0) delays
	 * the MISO capture point by N ssi_clk cycles to cover the on-SoM trace + crossed
	 * data round-trip.  Zephyr spi_dw never writes it (leaves 0), so without this
	 * >1 MHz mis-samples MISO (cold reqhdr_rx=0xFFFFFFFF).  Written with SSI disabled
	 * (SSIENR=0); persists across the driver's per-transfer configure.  Value is
	 * silicon-tuned -- sweep CC3501E_BRIDGE_RX_SAMPLE_DLY at the target SCLK.
	 *
	 * SWEEP TRAP -- read before setting the constant to 0: the `#if > 0` above
	 * compiles this block out, so 0 does not mean "no delay", it means the SPI
	 * node's `rx-delay` devicetree value is left in place.  aen-cc3501e-bringup
	 * and aen-evk-demo declare rx-delay = <2>, so a naive N=0 sweep point on
	 * those two silently measures 2.  Read 0x481040F0 back to see what the link
	 * is actually running at. */
	{
		volatile uint32_t *ssienr =
		    (volatile uint32_t *)(uintptr_t)(CC3501E_BRIDGE_SPI1_BASE + 0x08u);
		volatile uint32_t *rsd = (volatile uint32_t *)(uintptr_t)(CC3501E_BRIDGE_SPI1_BASE + 0xf0u);
		uint32_t           en  = *ssienr;
		*ssienr                = 0u;
		*rsd                   = (uint32_t)CC3501E_BRIDGE_RX_SAMPLE_DLY;
		*ssienr                = en;
	}
#endif

	/* 3. Bind the bus + control pins; attach the GPIO proxy (proxied E1M IOs then
	 *    route over the bridge); run the power + reset sequence (TI SWRU626 + the
	 *    Puya cold-boot hard-reset workaround).  Leaves WIFI_EN HIGH. */
	(void)cc3501e_init(fw, spi);
	fw->enable_pin = wifi_en;
	fw->reset_pin  = nrst;
	/* READY (CC35 GPIO17) is NOT wired here: fw->ready_pin stays NULL. No
	 * AEN example bridge wires it by default any more -- see
	 * chips/cc3501e/cc3501e_core.c's cc3501e_reply_gate() comment for the
	 * pin-routing fact and bench evidence behind that default, and this
	 * app's own overlay's `alp_pins` node (only WIFI_EN and E_WIFI.NRST --
	 * no gpio2 entry at all) for why there is nothing to open here even for
	 * an opt-in. */
#ifdef CONFIG_ALP_SDK_GPIO_CC3501E_PROXY
	(void)alp_gpio_cc3501e_attach(fw);
#endif
#ifdef CONFIG_ALP_SDK_WIFI_CC3501E
	(void)alp_wifi_cc3501e_attach(fw);
#endif
#ifdef CONFIG_ALP_SDK_BLE_CC3501E
	(void)alp_ble_cc3501e_attach(fw);
#endif
	return cc3501e_reset(fw);
}
```

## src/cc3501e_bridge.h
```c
/*
 * SPDX-License-Identifier: Apache-2.0
 * Copyright 2026 Alp Lab AB
 *
 * One-call bring-up of the E1M-AEN SoM's CC3501E Wi-Fi 6 / BLE coprocessor over the
 * inter-chip SPI bridge -- the SoM bring-up TEMPLATE for applications.
 *
 * The CC3501E is part of the SoM (module U4 = BDE-BW35N): the application does NOT
 * touch the raw SPI bus or the WIFI_EN / nRESET control pins.  It calls
 * cc3501e_bridge_bringup() once, gets a ready @ref cc3501e_t, and from there uses the
 * portable surfaces:
 *   - cc3501e_* (chips/cc3501e)            -- MAC / Wi-Fi / BLE / GPIO-proxy / OTA
 *   - alp_gpio_open(ALP_E1M_GPIO_IOxx)         -- proxied E1M IOs (when the proxy is built)
 *
 * To reuse in your own AEN application: copy this pair (cc3501e_bridge.{c,h}) into your
 * app, or call cc3501e_bridge_bringup() directly.  The bus / pins / clock are the
 * E1M-AEN SoM defaults below; a board variant overrides only those macros -- the SoM
 * stays swappable without touching application code.
 */

#ifndef CC3501E_BRIDGE_H
#define CC3501E_BRIDGE_H

#include <alp/peripheral.h>    /* alp_status_t */
#include <alp/chips/cc3501e.h> /* cc3501e_t */

/* ---- E1M-AEN SoM bridge defaults (override per board variant) ---------------- */

/* Inter-chip SPI: Alif = master, CC3501E = slave.  P14_7 is muxed as the
 * dwc-ssi hardware SS0 chip-select; ALP_SPI_NO_CS means "no software GPIO CS"
 * here, so the controller frames each protocol phase.  Mode 0 matches the
 * CC3501E vendor image frameFormat. */
#ifndef CC3501E_BRIDGE_SPI_BUS_ID
#define CC3501E_BRIDGE_SPI_BUS_ID 1u
#endif
#ifndef CC3501E_BRIDGE_SPI_FREQ_HZ
/* 25 MHz = 200 MHz SSI functional clock / 8.
 *
 * The CC3501E peripheral-mode maximum is 30 MHz, NOT the 15 MHz this comment
 * claimed for most of the bring-up: datasheet SWRS343A section 6.14.2.3.3,
 * `fsclk SPI clock frequency, Peripheral Mode, MAX 30 MHz` (Controller Mode is
 * 40 MHz).  Every earlier ceiling argument here was built on the wrong number.
 *
 * 25 MHz is the fastest LEGAL step available: the DW SSI BAUDR divisor must be
 * EVEN, so from 200 MHz the neighbours are /8 = 25 MHz and /6 = 33.3 MHz, and
 * 33.3 is 11% over the part's maximum.  Reaching exactly 30 MHz would require
 * retargeting the SSI functional clock itself (AE822 HWRM section 8.3.5) --
 * ALIF_SPI_CLK is a frequency-only dummy in the dtsi with no divider control,
 * so there is no software knob for it here.
 *
 * REQUIRES an RX sample delay: at a 40 ns bit period the MISO capture does not
 * land on its own.  That delay comes from CC3501E_BRIDGE_RX_SAMPLE_DLY below --
 * NOT from the SPI node's `rx-delay` property, which the poke in
 * cc3501e_bridge.c overwrites.  The measured working span is in that constant's
 * comment.
 *
 * It does not raise throughput -- silicon-measured
 * 2026-08-24: 682 kB/s at 25 MHz vs 678 kB/s at 14.29 MHz on PIO, 704 vs 701 on
 * DMA, because wire time is only ~554 us of a ~2459 us transaction and the rest
 * is per-frame protocol cost on both ends.  It is worth taking anyway: each
 * transfer occupies the bus for ~44% less time, which is CPU and bus budget
 * handed back to everything else on the SoM.
 *
 * The 14.29 MHz predecessor was scope-confirmed at 14.20-14.26 MHz, which is
 * what validates the 200 MHz functional-clock figure the divider assumes.  A
 * board with longer traces should re-check MISO capture before adopting 25 MHz.
 *
 * SEPARATE, PRE-EXISTING DEFECT (do not blame this clock for it): a bulk read
 * intermittently desyncs partway through -- roughly 1 run in 2-3, at anywhere
 * from 61 kB to 212 kB in -- and then never recovers for the caller's whole
 * retry budget.  It reproduces at 14.29 MHz TOO, so it is not a clock artifact.
 * Signature (host-side, request-header phase of CMD_SOCK_RECV 0x23): the
 * slave's in-band idle marker reads [02 00 00 00] once and then [00 00 00 00]
 * forever instead of A5 A5 A5 A5 -- i.e. the slave is stuck mid-reply on a
 * transfer it armed earlier and never completed.  With
 * SPI_TRANSFER_RETURN_PARTIAL deliberately off, a CS deassert does not complete
 * it, and NEITHER slave self-heal fires (g_resync_count does not move -- the
 * slave is not misframing; g_arm_fail_count does not move -- the arm succeeded).
 * Clocking a full idle frame from the host to satisfy the outstanding count was
 * tried and did NOT recover it.  The fix likely belongs on the slave: a
 * stall watchdog that calls bridge_transport_spi_hw_reinit() when an armed
 * transfer has not completed for N ms. */
#define CC3501E_BRIDGE_SPI_FREQ_HZ 25000000u
#endif

/* CC3501E control pins on the Alif LP-GPIO island (NOT E1M edge pads):
 * WIFI_EN = supply gate (P15_5), nRESET = reset (P15_1_FLEX). */
#ifndef CC3501E_BRIDGE_PIN_WIFI_EN
#define CC3501E_BRIDGE_PIN_WIFI_EN 0u
#endif
#ifndef CC3501E_BRIDGE_PIN_NRST
#define CC3501E_BRIDGE_PIN_NRST 1u
#endif
/* OPTIONAL host-IRQ/READY input (CC35 GPIO17, alp_pins[2]).  When the board
 * wires it, cc3501e_request() gates reply phases on it (HIGH = slave armed)
 * instead of a fixed delay.  Absent -> ready_pin NULL -> legacy gap.
 *
 * NOT the same net as Alif P2_6: on e1m-aen-evk-01, P2_6 is E1M pad AH7 /
 * I2S1_SCLK (the EVK's Arduino CK_RST, metadata/boards/e1m-evk.yaml), and the
 * CC3501E GPIO17 READY net lands on E1M pad G3 / IO16 instead
 * (metadata/e1m_modules/aen/from-cc3501e.tsv).  cc3501e_bridge_bringup()
 * below does not open this pin on that board -- see its comment for the
 * bench evidence -- so this macro currently has no live consumer here.
 * THIS APP'S OWN overlay never declares an `alp_pins` index [2] at all
 * (unlike the sibling AEN examples this template is copied from, whose
 * alp_pins[2] does point at &gpio2 6): alp_gpio_open(CC3501E_BRIDGE_PIN_READY)
 * would fail to resolve here even if something tried to call it. */
#ifndef CC3501E_BRIDGE_PIN_READY
#define CC3501E_BRIDGE_PIN_READY 2u
#endif

/* DW SSI SPI1 base (0x48104000) + RX_SAMPLE_DLY to run the bridge SCLK above
 * 1 MHz.  spi_dw_configure never writes RX_SAMPLE_DLY (0xf0), so without the
 * poke in cc3501e_bridge.c the master samples MISO at the SCLK edge, before the
 * on-SoM trace + crossed-data round-trip returns the CC35's bit, and anything
 * above 1 MHz mis-samples.  Setting it delays the capture by N ssi_clk
 * (200 MHz) cycles -- 5 ns per step.
 *
 * 4 is silicon-measured at the 25 MHz working point (40 ns bit period) on
 * E1M-AEN803 serial 2026W36-0002.  N was swept 0..10 with 0x481040F0 read back
 * each time to confirm the value took, using aen-evk-demo phase 8 as the
 * workload:
 *
 *   N = 0..7   PASS, 2-3 runs each: bring-up 0, PING on attempt 1 of 25,
 *              byte-exact MAC, scan 0, BLE 0.
 *   N = 8      FAIL, 3 runs of 3: bring-up still returns 0, but the link never
 *              answers -- PING -> -5 after all 25 attempts.
 *   N = 9      PASS, 2 runs of 2.
 *   N = 10     PASS, 3 runs of 3, but one run returned a MAC with a single bit
 *              flipped in byte 0.
 *
 * 4 is the centre of the measured-good 0..7 span: +4 steps (20 ns, half a bit
 * period) below the failure, and the low side is not a cliff at all since 0
 * itself is clean.  Do NOT read 8/9/10 as a monotone upper boundary -- 8
 * hard-fails while 9 and 10 pass, which this sweep did not explain.  Treat
 * everything above 7 as unqualified, not as graded margin.
 *
 * The "4..8 all clean cold+warm" window this comment used to claim was taken on
 * e1m-aen-evk-01 at ~14.3 MHz -- a different board at roughly half the clock,
 * so it is not comparable and is not evidence for 25 MHz on this one.
 *
 * 0 does NOT mean "no delay": it compiles the poke out, leaving whatever the
 * SPI node's `rx-delay` property put there (see cc3501e_bridge.c).  Re-sweep if
 * the SoM trace lengths or the SCLK change. */
#ifndef CC3501E_BRIDGE_SPI1_BASE
#define CC3501E_BRIDGE_SPI1_BASE 0x48104000u
#endif
#ifndef CC3501E_BRIDGE_RX_SAMPLE_DLY
#define CC3501E_BRIDGE_RX_SAMPLE_DLY 4u
#endif

/**
 * @brief Bring up the SoM's CC3501E coprocessor over the inter-chip bridge.
 *
 * Opens the hardware-SS0 bridge SPI + the WIFI_EN / nRESET control pins, binds
 * them to @p fw, attaches the GPIO proxy (when CONFIG_ALP_SDK_GPIO_CC3501E_PROXY is
 * built), and runs the power + reset sequence (TI SWRU626 + the Puya cold-boot
 * hard-reset workaround).  Blocks ~900 ms for the boot budget; leaves WIFI_EN HIGH.
 *
 * @param fw  Caller-owned handle, populated on success.  Use it with cc3501e_*.
 * @return ALP_OK with @p fw ready; ALP_ERR_NOT_PRESENT_ON_THIS_SOC if the SPI bus /
 *         control pins are absent (check the board overlay); otherwise the reset
 *         sequence status.  On any failure @p fw is left un-bound (do not use it).
 */
alp_status_t cc3501e_bridge_bringup(cc3501e_t *fw);

#endif /* CC3501E_BRIDGE_H */
```

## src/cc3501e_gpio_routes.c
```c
/*
 * SPDX-License-Identifier: Apache-2.0
 * Copyright 2026 Alp Lab AB
 *
 * Auto-generated for aen-cc3501e-gpio by scripts/gen_cc3501e_gpio_routes.py
 * from metadata/e1m_modules/E1M-AEN801.yaml `pad_routes:` (resolved for
 * hw_rev=r2 -- see metadata/e1m_modules/aen/hw-revisions.yaml
 * `pad_route_overrides:` when board.yaml sets `som.hw_rev:`).
 * DO NOT EDIT BY HAND -- regenerate:
 *   python3 scripts/gen_cc3501e_gpio_routes.py
 *
 * Strong override of the WEAK cc3501e_gpio_routes[] /
 * cc3501e_gpio_route_count in
 * src/backends/gpio/cc3501e_proxy_routes_weak.c.  Maps the portable E1M
 * GPIO pin_id (alp_gpio_open(ALP_E1M_GPIO_IOxx)) to the RAW CC3501E GPIO
 * index the inter-chip bridge drives, so an alp_gpio_* call on a proxied
 * E1M IO is routed over the bridge while the Alif's own pins delegate to
 * the platform driver.
 *
 * Pads whose CC3501E target is bridge-reserved (the transport's own
 * SPI0 / console pads, or the bridge's own READY/host-IRQ + SPI0-CS
 * lines) are never emitted here -- the firmware's gpio_pad_reserved()
 * would refuse them at runtime, so the generator excludes them at
 * generation time instead (issue #1859).
 *
 * The revision-dependent pin guard (issue #2144) is NOT emitted here --
 * it does not depend on this board's own routes, so it lives in ONE
 * SDK-owned generated file instead of a per-app copy:
 * src/backends/gpio/cc3501e_rev_dependent_pins.c.
 */

#include <stdint.h>
#include <stddef.h>

#include <alp/chips/cc3501e.h>
#include <alp/e1m_pinout.h>

const cc3501e_gpio_route_t cc3501e_gpio_routes[] = {
	{ ALP_E1M_GPIO_IO8, 30u }, /* I2S0 74LVC157 /E, active low. CC3501E-proxied, not an Alif pin. */
	{ ALP_E1M_GPIO_IO9, 12u }, /* Reset output to the PCIe IO expander. */
	{ ALP_E1M_GPIO_IO10, 35u }, /* Drive high to enable I2C mux to the PCIe slot. */
	{ ALP_E1M_GPIO_IO11, 2u },  /* USB2 TMUXHS221 select: 0 = USB connector, 1 = M.2 E-key USB. */
	{ ALP_E1M_GPIO_IO13, 13u }, /* I2S0 74LVC157 S; 0 = TAS2563 amps, 1 = M.2 E-key I2S. */
	{ ALP_E1M_GPIO_IO15, 14u }, /* BMI323 INT1 (data-ready / motion / FIFO); CC3501E GPIO14. */
	{ ALP_E1M_GPIO_IO18, 18u }, /* M.2 E-key SDIO-path wake (active-low). */
	{ ALP_E1M_GPIO_IO19, 19u }, /* M.2 E-key UART-path wake (active-low). */
	{ ALP_E1M_GPIO_IO20, 26u }, /* SDIO 74LVC157 /E; drive low to enable mux. */
};

const size_t cc3501e_gpio_route_count =
    sizeof(cc3501e_gpio_routes) / sizeof(cc3501e_gpio_routes[0]);
```
